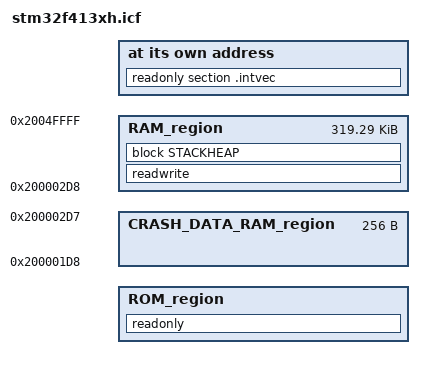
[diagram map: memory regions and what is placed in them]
/* Linker script to configure memory regions.
 *
 * SPDX-License-Identifier: BSD-3-Clause
 ******************************************************************************
 * @attention
 *
 * Copyright (c) 2016-2020 STMicroelectronics.
 * All rights reserved.
 *
 * This software component is licensed by ST under BSD 3-Clause license,
 * the "License"; You may not use this file except in compliance with the
 * License. You may obtain a copy of the License at:
 *                        opensource.org/licenses/BSD-3-Clause
 *
 ******************************************************************************
*/
/* Device specific values */

/* Tools provide -DMBED_ROM_START=xxx -DMBED_ROM_SIZE=xxx -DMBED_RAM_START=xxx -DMBED_RAM_SIZE=xxx */

/* [ROM = 1536kb = 0x180000] */
if (!isdefinedsymbol(MBED_APP_START)) { define symbol MBED_APP_START = 0x08000000; }
if (!isdefinedsymbol(MBED_APP_SIZE)) { define symbol MBED_APP_SIZE = 0x180000; }

define symbol __intvec_start__     = MBED_APP_START;
define symbol __region_ROM_start__ = MBED_APP_START;
define symbol __region_ROM_end__   = MBED_APP_START + MBED_APP_SIZE - 1;

/* [RAM = 320kb = 0x50000] Vector table dynamic copy: 118 vectors = 472 bytes (0x1D8) to be reserved in RAM */
define symbol __NVIC_start__          = 0x20000000;
define symbol __NVIC_end__            = 0x200001D7;
define symbol __region_CRASH_DATA_RAM_start__  = 0x200001D8;
define symbol __region_CRASH_DATA_RAM_end__    = 0x200002D7;
define symbol __region_RAM_start__    = 0x200002D8; /* Aligned on 8 bytes */
define symbol __region_RAM_end__      = 0x2004FFFF;

/* Memory regions */
define memory mem with size = 4G;
define region ROM_region = mem:[from __region_ROM_start__ to __region_ROM_end__];
define region CRASH_DATA_RAM_region = mem:[from __region_CRASH_DATA_RAM_start__ to __region_CRASH_DATA_RAM_end__];
define region RAM_region = mem:[from __region_RAM_start__ to __region_RAM_end__];

/* Define Crash Data Symbols */
define exported symbol __CRASH_DATA_RAM_START__ = __region_CRASH_DATA_RAM_start__;
define exported symbol __CRASH_DATA_RAM_END__ = __region_CRASH_DATA_RAM_end__;

/* Stack and Heap */
if (!isdefinedsymbol(MBED_CONF_TARGET_BOOT_STACK_SIZE)) {
    define symbol MBED_CONF_TARGET_BOOT_STACK_SIZE = 0x400;
}
define symbol __size_cstack__ = MBED_CONF_TARGET_BOOT_STACK_SIZE;
define symbol __size_heap__   = 0x10000;
define block CSTACK    with alignment = 8, size = __size_cstack__   { };
define block HEAP      with alignment = 8, size = __size_heap__     { };
define block STACKHEAP with fixed order { block HEAP, block CSTACK };

initialize by copy with packing = zeros { readwrite };
do not initialize  { section .noinit };

place at address mem:__intvec_start__ { readonly section .intvec };

place in ROM_region   { readonly };
place in RAM_region   { readwrite, block STACKHEAP };
